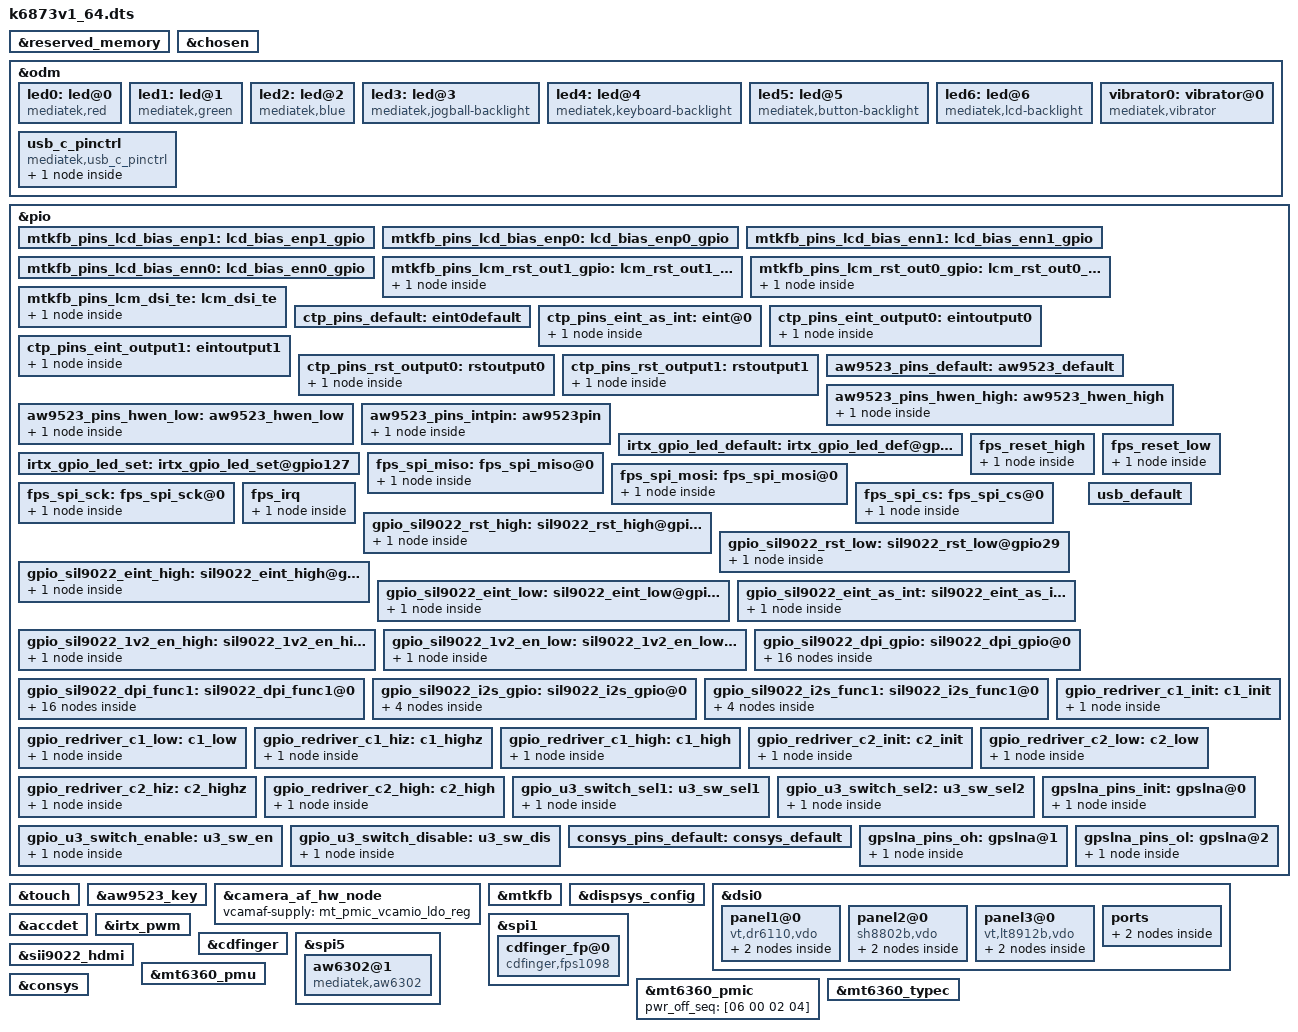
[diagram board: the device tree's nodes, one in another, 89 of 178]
/*
 * Mediatek's mt6873 SoC device tree source
 *
 * Copyright (C) 2016 MediaTek Inc.
 *
 * This program is free software; you can redistribute it and/or modify
 * it under the terms of the GNU General Public License version 2 as
 * published by the Free Software Foundation.
 *
 * This program is distributed in the hope that it will be useful,
 * but WITHOUT ANY WARRANTY; without even the implied warranty of
 * MERCHANTABILITY or FITNESS FOR A PARTICULAR PURPOSE.
 * See http://www.gnu.org/licenses/gpl-2.0.html for more details.
 */
/dts-v1/;
/plugin/;
#include <dt-bindings/interrupt-controller/irq.h>
#include <dt-bindings/interrupt-controller/arm-gic.h>
#include <dt-bindings/pinctrl/mt6873-pinfunc.h>

&reserved_memory {
};

/* chosen */
&chosen {

	atag,videolfb-fb_base_l = <0x7e605000>;
	atag,videolfb-fb_base_h = <0x0>;
	atag,videolfb-islcmfound = <1>;
	atag,videolfb-islcm_inited = <0>;
	atag,videolfb-fps= <6000>;
	atag,videolfb-vramSize= <0x1be0000>;
	atag,videolfb-lcmname=
		"nt35595_fhd_dsi_cmd_truly_nt50358_drv";
};

&odm {
	led0:led@0 {
		compatible = "mediatek,red";
		led_mode = <0>;
		data = <1>;
		pwm_config = <0 0 0 0 0>;
	};
	led1:led@1 {
		compatible = "mediatek,green";
		led_mode = <0>;
		data = <1>;
		pwm_config = <0 0 0 0 0>;
	};
	led2:led@2 {
		compatible = "mediatek,blue";
		led_mode = <0>;
		data = <1>;
		pwm_config = <0 0 0 0 0>;
	};
	led3:led@3 {
		compatible = "mediatek,jogball-backlight";
		led_mode = <0>;
		data = <1>;
		pwm_config = <0 0 0 0 0>;
	};
	led4:led@4 {
		compatible = "mediatek,keyboard-backlight";
		led_mode = <0>;
		data = <1>;
		pwm_config = <0 0 0 0 0>;
	};
	led5:led@5 {
		compatible = "mediatek,button-backlight";
		led_mode = <0>;
		data = <1>;
		pwm_config = <0 0 0 0 0>;
	};
	led6:led@6 {
		compatible = "mediatek,lcd-backlight";
		led_mode = <4>;
		data = <1>;
		pwm_config = <0 1 0 0 0>;
	};
	vibrator0:vibrator@0 {
		compatible = "mediatek,vibrator";
		vib_timer = <25>;
		vib_limit = <9>;
		vib_vol= <9>;
	};
	usb_c_pinctrl:usb_c_pinctrl {
		compatible = "mediatek,usb_c_pinctrl";
	};
};

/* DISPSYS GPIO standardization */

&pio {
	mtkfb_pins_lcd_bias_enp1: lcd_bias_enp1_gpio {
		//pins_cmd_dat {
			//pinmux = <PINMUX_GPIO28__FUNC_GPIO28>;
			//slew-rate = <1>;
			//output-high;
		//};
	};

	mtkfb_pins_lcd_bias_enp0: lcd_bias_enp0_gpio {
		//pins_cmd_dat {
			//pinmux = <PINMUX_GPIO28__FUNC_GPIO28>;
			//slew-rate = <1>;
			//output-low;
		//};
	};

	mtkfb_pins_lcd_bias_enn1: lcd_bias_enn1_gpio {
		//pins_cmd_dat {
			//pinmux = <PINMUX_GPIO29__FUNC_GPIO29>;
			//slew-rate = <1>;
			//output-high;
		//};
	};

	mtkfb_pins_lcd_bias_enn0: lcd_bias_enn0_gpio {
		//pins_cmd_dat {
			//pinmux = <PINMUX_GPIO29__FUNC_GPIO29>;
			//slew-rate = <1>;
			//output-low;
		//};
	};

	mtkfb_pins_lcm_rst_out1_gpio: lcm_rst_out1_gpio {
		pins_cmd_dat {
			pinmux = <PINMUX_GPIO42__FUNC_GPIO42>;
			slew-rate = <1>;
			output-high;
		};
	};

	mtkfb_pins_lcm_rst_out0_gpio: lcm_rst_out0_gpio {
		pins_cmd_dat {
			pinmux = <PINMUX_GPIO42__FUNC_GPIO42>;
			slew-rate = <1>;
			output-low;
		};
	};
	mtkfb_pins_lcm_dsi_te: lcm_dsi_te {
		pins_cmd_dat {
			pinmux = <PINMUX_GPIO41__FUNC_DSI_TE>;
		};
	};
};
/* TOUCH start */
&touch {
	tpd-resolution = <1080 2340>;
	use-tpd-button = <0>;
	tpd-key-num = <3>;
	tpd-key-local= <139 172 158 0>;
	tpd-key-dim-local = <90 883 100 40 230 883 100 40 370 883 100 40 0 0 0 0>;
	tpd-max-touch-num = <5>;
	tpd-filter-enable = <1>;
	tpd-filter-pixel-density = <146>;
	tpd-filter-custom-prameters = <0 0 0 0 0 0 0 0 0 0 0 0>;
	tpd-filter-custom-speed = <0 0 0>;
	pinctrl-names = "default", "state_eint_as_int", "state_eint_output0", "state_eint_output1",
		"state_rst_output0", "state_rst_output1";
	pinctrl-0 = <&ctp_pins_default>;
	pinctrl-1 = <&ctp_pins_eint_as_int>;
	pinctrl-2 = <&ctp_pins_eint_output0>;
	pinctrl-3 = <&ctp_pins_eint_output1>;
	pinctrl-4 = <&ctp_pins_rst_output0>;
	pinctrl-5 = <&ctp_pins_rst_output1>;
	status = "okay";
};

&pio {
	ctp_pins_default: eint0default {
	};
	ctp_pins_eint_as_int: eint@0 {
		pins_cmd_dat {
			pinmux = <PINMUX_GPIO21__FUNC_GPIO21>;
			slew-rate = <0>;
			bias-disable;
		};
	};
	ctp_pins_eint_output0: eintoutput0 {
		pins_cmd_dat {
			pinmux = <PINMUX_GPIO21__FUNC_GPIO21>;
			slew-rate = <1>;
			output-low;
		};
	};
	ctp_pins_eint_output1: eintoutput1 {
		pins_cmd_dat {
			pinmux = <PINMUX_GPIO21__FUNC_GPIO21>;
			slew-rate = <1>;
			output-high;
		};
	};
	ctp_pins_rst_output0: rstoutput0 {
		pins_cmd_dat {
			pinmux = <PINMUX_GPIO20__FUNC_GPIO20>;
			slew-rate = <1>;
			output-low;
		};
	};
	ctp_pins_rst_output1: rstoutput1 {
		pins_cmd_dat {
			pinmux = <PINMUX_GPIO20__FUNC_GPIO20>;
			slew-rate = <1>; 
			output-high;
		}; 
	};
};
/* TOUCH end */
&aw9523_key {
	pinctrl-names = "default","aw9523_shdn_high","aw9523_shdn_low","aw9523_int_pin";
	pinctrl-0 = <&aw9523_pins_default>;
	pinctrl-1 = <&aw9523_pins_hwen_high>;
	pinctrl-2 = <&aw9523_pins_hwen_low>;
	pinctrl-3 = <&aw9523_pins_intpin>;
	status = "okay";
};
&pio {
	aw9523_pins_default: aw9523_default {
	};
	aw9523_pins_hwen_high: aw9523_hwen_high {
	    pins_cmd_dat {
			pinmux = <PINMUX_GPIO5__FUNC_GPIO5>;
			slew-rate = <1>;
			output-high;
		};
	};
	aw9523_pins_hwen_low: aw9523_hwen_low {
	    pins_cmd_dat {
			pinmux = <PINMUX_GPIO5__FUNC_GPIO5>;
			slew-rate = <1>;
			output-low;
		};
	};
    aw9523_pins_intpin: aw9523pin{
        pins_cmd_dat {
            pinmux = <PINMUX_GPIO2__FUNC_GPIO2>;
            slew-rate = <0>;
            bias-pull-up = <00>;
        };
    };
};


&camera_af_hw_node {
	vcamaf-supply = <&mt_pmic_vcamio_ldo_reg>;
	status = "okay";
};

&mtkfb {
	pinctrl-names = "lcd_bias_enp1_gpio", "lcd_bias_enp0_gpio",
		"lcd_bias_enn1_gpio", "lcd_bias_enn0_gpio",
		"lcm_rst_out1_gpio", "lcm_rst_out0_gpio",
		"mode_te_te";
	pinctrl-0 = <&mtkfb_pins_lcd_bias_enp1>;
	pinctrl-1 = <&mtkfb_pins_lcd_bias_enp0>;
	pinctrl-2 = <&mtkfb_pins_lcd_bias_enn1>;
	pinctrl-3 = <&mtkfb_pins_lcd_bias_enn0>;
	pinctrl-4 = <&mtkfb_pins_lcm_rst_out1_gpio>;
	pinctrl-5 = <&mtkfb_pins_lcm_rst_out0_gpio>;
	pinctrl-6 = <&mtkfb_pins_lcm_dsi_te>;
	status = "okay";
};

&dispsys_config {
	pinctrl-names =
		"lcm_rst_out1_gpio", "lcm_rst_out0_gpio",
		"mode_te_te";
	pinctrl-0 = <&mtkfb_pins_lcm_rst_out1_gpio>;
	pinctrl-1 = <&mtkfb_pins_lcm_rst_out0_gpio>;
	pinctrl-2 = <&mtkfb_pins_lcm_dsi_te>;
	status = "okay";
};

&dsi0 {
	status = "okay";
	#address-cells = <1>;
	#size-cells = <0>;
	panel1@0 {
		compatible = "vt,dr6110,vdo";
		reg = <0>;
		pm-enable-gpios = <&pio 41 0>;
		reset-gpios = <&pio 42 0>;
		bias-gpios = <&pio 87 0>,
			<&pio 88 0>;
		pinctrl-names = "default";
		port {
			panel_in1: endpoint {
				remote-endpoint = <&dsi_out>;
			};
		};
	};
	panel2@0 {
		compatible = "sh8802b,vdo";
		reg = <1>;
		pm-enable-gpios = <&pio 41 0>;
		reset-gpios = <&pio 42 0>;
		bias-gpios = <&pio 87 0>,
			<&pio 88 0>;
		pinctrl-names = "default";
		port {
			panel_in2: endpoint {
				remote-endpoint = <&dsi_out>;
			};
		};
	};
	panel3@0 {
		compatible = "vt,lt8912b,vdo";
		reg = <2>;
		pm-enable-gpios = <&pio 41 0>;
		reset-gpios = <&pio 42 0>;
		bias-gpios = <&pio 87 0>,
			<&pio 88 0>;
		pinctrl-names = "default";
		port {
			panel_in3: endpoint {
				remote-endpoint = <&dsi_out>;
			};
		};
	};
	ports {
		port {
			dsi_out: endpoint {
				remote-endpoint = <&panel_in1>;
			};
		};
	};
};

/* accdet start */
&accdet {
	/* accdet micbias voltage: 0x09:2.85v 0x08:2.8v 0x07,
	 * 2.7v;0x05,2.5v;0x02,1.9v
	 */
	accdet-mic-vol = <8>;
	/* accdet pwm_width, pwm_thresh, fall_delay, rise_delay
	 * debounce0, debounce1, debounce3, debounce4
	 * eint pwm_width, eint pwm_thresh
	 * eint deb(debounce0, debounce1, debounce2, debounce3), inv_debounce
	 */
	headset-mode-setting = <0x500 0x500 1 0x1f0
				0x800 0x800 0x20 0x44
				0x4 0x1
				0x5 0x3 0x3 0x5 0xe>;
	accdet-plugout-debounce = <1>;
	/*1:ACC mode, 2:low cost without in bias, 6:low cost with in bias*/
	accdet-mic-mode = <2>;
	/*0--MD_MAX--UP_MAX--DW_MAX*/
	headset-three-key-threshold = <0 80 220 400>;
	headset-three-key-threshold-CDD = <0 121 192 600>;
	/*0--MD_MAX--VOICE_MAX--UP_MAX--DW_MAX*/
	headset-four-key-threshold = <0 58 121 192 400>;

	/* select VTH to 2v and 500k, use internal resitance */
	eint_use_ext_res = <0>;
	status = "okay";
};
/* accdet end */

/* IRTX GPIO Start */
&irtx_pwm {
	pinctrl-names = "irtx_gpio_led_default", "irtx_gpio_led_set";
	pinctrl-0 = <&irtx_gpio_led_default>;
	pinctrl-1 = <&irtx_gpio_led_set>;
	status = "okay";
};
&pio {
	/* IRTX GPIO Settings -Start */
	/* default: GPIO0, output, high */
	irtx_gpio_led_default:irtx_gpio_led_def@gpio127 {
		//pins_cmd_dat {
			//pinmux = <PINMUX_GPIO127__FUNC_GPIO127>;
			//slew-rate = <1>;
			//bias-disable;
			//output-low;
			//input-schmitt-enable = <0>;
		//};
	};

	irtx_gpio_led_set:irtx_gpio_led_set@gpio127 {
		//pins_cmd_dat {
			//pinmux = <PINMUX_GPIO127__FUNC_PWM_3>;
			//slew-rate = <1>;
			//output-high;
		//};
	};
}; /* IRTX GPIO Settings -End */

/************Cdfinger FINGERPRINT bengin *********/
&pio {
	fps_reset_high: fps_reset_high {
		pins_cmd_dat {
			pinmux = <PINMUX_GPIO14__FUNC_GPIO14>;
			slew-rate = <1>;
			bias-disable;
			output-high;
		};
	};
	fps_reset_low: fps_reset_low {
		pins_cmd_dat {
			pinmux = <PINMUX_GPIO14__FUNC_GPIO14>;
			slew-rate = <1>;
			bias-disable;
			output-low;
		};
	};
	fps_spi_miso:fps_spi_miso@0{
		pins_cmd_dat {
			pinmux = <PINMUX_GPIO158__FUNC_SPI1_A_MI>;
			slew-rate = <0>;
			bias-disable;
			output-low;
		};
	};
	fps_spi_mosi:fps_spi_mosi@0{
		pins_cmd_dat {
			pinmux = <PINMUX_GPIO159__FUNC_SPI1_A_MO>;
			slew-rate = <1>;
			bias-disable;
			output-low;
		};
	};
	fps_spi_sck:fps_spi_sck@0{
		pins_cmd_dat {
			pinmux = <PINMUX_GPIO156__FUNC_SPI1_A_CLK>;
			slew-rate = <1>;
			bias-disable;
			output-low;
		};
	};
	fps_spi_cs:fps_spi_cs@0{
		pins_cmd_dat {
			pinmux = <PINMUX_GPIO157__FUNC_SPI1_A_CSB>;
			slew-rate = <1>;
			bias-pull-up = <11>;
			bias-disable;
			output-low;
		};
	};
	fps_irq: fps_irq {
		pins_cmd_dat {
			pinmux = <PINMUX_GPIO15__FUNC_GPIO15>;
			slew-rate = <0>;
			bias-pull-down = <00>;
			bias-disable;
			output-low;
		};
	};
};

&spi1 {
	#address-cells = <1>;
	#size-cells = <0>;
  
	 cdfinger_fp@0{                               
		compatible = "cdfinger,fps1098";		
		reg = <0x0>;                                
		spi-max-frequency = <0x10000000>;	          
		status = "okay";                            
	 };                                       
	                                       
};

&cdfinger {
	interrupt-parent = <&pio>;
	interrupts = <15 1 1 0>;
	/*interrupts = <15 IRQ_TYPE_EDGE_RISING 1 0>;*/
	vfp-supply = <&mt_pmic_vfp_ldo_reg>;
	vdd_ldo_enable = <0>;
	vio_ldo_enable = <0>;
	config_spi_pin = <1>;
	
	
	pinctrl-names = "fingerprint_reset_high",
		"fingerprint_reset_low",
		"fingerprint_spi_miso",
		"fingerprint_spi_mosi",
		"fingerprint_spi_sck",
		"fingerprint_spi_cs",
		"fingerprint_irq";
	pinctrl-0 = <&fps_reset_high>;
	pinctrl-1 = <&fps_reset_low>;
	pinctrl-2 = <&fps_spi_miso>;
	pinctrl-3 = <&fps_spi_mosi>;
	pinctrl-4 = <&fps_spi_sck>;
	pinctrl-5 = <&fps_spi_cs>;
	pinctrl-6 = <&fps_irq>;
	status = "okay";

};
/************Cdfinger FINGERPRINT end *********/

&spi5 {
    #address-cells = <1>;
    #size-cells = <0>;
    aw6302@1 {
        compatible = "mediatek,aw6302";
        reg = <0>;
        spi-max-frequency = <1500000>;
        status = "okay";
    };
};

/*sil9022 hdmi start*/
&sii9022_hdmi {
	pinctrl-names = "sil9022_rst_high","sil9022_rst_low","sil9022_eint_high","sil9022_eint_low","sil9022_eint_as_int",
			"sil9022_1v2_en_high","sil9022_1v2_en_low","sil9022_dpi_gpio","sil9022_dpi_func1","sil9022_i2s_gpio","sil9022_i2s_func1";		
	pinctrl-0 = <&gpio_sil9022_rst_high>;
	pinctrl-1 = <&gpio_sil9022_rst_low>;
	pinctrl-2 = <&gpio_sil9022_eint_high>;
	pinctrl-3 = <&gpio_sil9022_eint_low>;
	pinctrl-4 = <&gpio_sil9022_eint_as_int>;
	pinctrl-5 = <&gpio_sil9022_1v2_en_high>;
	pinctrl-6 = <&gpio_sil9022_1v2_en_low>;
	pinctrl-7 = <&gpio_sil9022_dpi_gpio>;
	pinctrl-8 = <&gpio_sil9022_dpi_func1>;
	pinctrl-9 = <&gpio_sil9022_i2s_gpio>;
	pinctrl-10 = <&gpio_sil9022_i2s_func1>;	
	status = "okay";
};

&pio {

	gpio_sil9022_rst_high:sil9022_rst_high@gpio29 {
		pins_cmd_dat {
			pinmux = <PINMUX_GPIO29__FUNC_GPIO29>;
			slew-rate = <1>;
			output-high;
		};
	};

	gpio_sil9022_rst_low:sil9022_rst_low@gpio29 {
		pins_cmd_dat {
			pinmux = <PINMUX_GPIO29__FUNC_GPIO29>;
			slew-rate = <1>;
			output-low;
		};
	};
	
	gpio_sil9022_eint_high:sil9022_eint_high@gpio7 {
		pins_cmd_dat {
			pinmux = <PINMUX_GPIO7__FUNC_GPIO7>;
			slew-rate = <1>;
			output-high;
		};
	};

	gpio_sil9022_eint_low:sil9022_eint_low@gpio7 {
		pins_cmd_dat {
			pinmux = <PINMUX_GPIO7__FUNC_GPIO7>;
			slew-rate = <1>;
			output-low;
		};
	};
	
	gpio_sil9022_eint_as_int:sil9022_eint_as_int@7 {
		pins_cmd_dat {
			pinmux = <PINMUX_GPIO7__FUNC_GPIO7>;
			slew-rate = <0>;
			bias-disable;
		};
	};	

	gpio_sil9022_1v2_en_high:sil9022_1v2_en_high@gpio18 {
		pins_cmd_dat {
			pinmux = <PINMUX_GPIO18__FUNC_GPIO18>;
			slew-rate = <1>;
			output-high;
		};
	};
	
	gpio_sil9022_1v2_en_low:sil9022_1v2_en_low@gpio18 {
		pins_cmd_dat {
			pinmux = <PINMUX_GPIO18__FUNC_GPIO18>;
			slew-rate = <1>;
			output-low;
		};
	};	

	gpio_sil9022_dpi_gpio: sil9022_dpi_gpio@0 {
		pins_cmd0_dat {
			pinmux = <PINMUX_GPIO96__FUNC_GPIO96>;
			slew-rate = <1>;
			output-low;
			bias-disable;
			drive-strength= <7>;
		};
		pins_cmd1_dat {
			pinmux = <PINMUX_GPIO97__FUNC_GPIO97>;
			slew-rate = <1>;
			output-low;
			bias-disable;
			drive-strength= <7>;
		};
		pins_cmd2_dat {
			pinmux = <PINMUX_GPIO98__FUNC_GPIO98>;
			slew-rate = <1>;
			output-low;
			bias-disable;
			drive-strength= <7>;
		};
		pins_cmd3_dat {
			pinmux = <PINMUX_GPIO99__FUNC_GPIO99>;
			slew-rate = <1>;
			output-low;
			bias-disable;
			drive-strength= <7>;
		};
		pins_cmd4_dat {
			pinmux = <PINMUX_GPIO100__FUNC_GPIO100>;
			slew-rate = <1>;
			output-low;
			bias-disable;
			drive-strength= <7>;
		};
		pins_cmd5_dat {
			pinmux = <PINMUX_GPIO101__FUNC_GPIO101>;
			slew-rate = <1>;
			output-low;
			bias-disable;
			drive-strength= <7>;
		};
		pins_cmd6_dat {
			pinmux = <PINMUX_GPIO102__FUNC_GPIO102>;
			slew-rate = <1>;
			output-low;
			bias-disable;
			drive-strength= <7>;
		};
		pins_cmd7_dat {
			pinmux = <PINMUX_GPIO103__FUNC_GPIO103>;
			slew-rate = <1>;
			output-low;
			bias-disable;
			drive-strength= <7>;
		};
		pins_cmd8_dat {
			pinmux = <PINMUX_GPIO104__FUNC_GPIO104>;
			slew-rate = <1>;
			output-low;
			bias-disable;
			drive-strength= <7>;
		};
		pins_cmd9_dat {
			pinmux = <PINMUX_GPIO105__FUNC_GPIO105>;
			slew-rate = <1>;
			output-low;
			bias-disable;
			drive-strength= <7>;
		};
		pins_cmd10_dat {
			pinmux = <PINMUX_GPIO106__FUNC_GPIO106>;
			slew-rate = <1>;
			output-low;
			bias-disable;
			drive-strength= <7>;
		};
		pins_cmd11_dat {
			pinmux = <PINMUX_GPIO110__FUNC_GPIO110>;
			slew-rate = <1>;
			output-low;
			bias-disable;
			drive-strength= <7>;
		};
		pins_cmd12_dat {
			pinmux = <PINMUX_GPIO109__FUNC_GPIO109>;
			slew-rate = <1>;
			output-low;
			bias-disable;
			drive-strength= <7>;
		};
		pins_cmd13_dat {
			pinmux = <PINMUX_GPIO112__FUNC_GPIO112>;
			slew-rate = <1>;
			output-low;
			bias-disable;
			drive-strength= <7>;
		};
		pins_cmd14_dat {
			pinmux = <PINMUX_GPIO113__FUNC_GPIO113>;
			slew-rate = <1>;
			output-low;
			bias-disable;
			drive-strength= <7>;
		};
		pins_cmd15_dat {
			pinmux = <PINMUX_GPIO111__FUNC_GPIO111>;
			slew-rate = <1>;
			output-low;
			bias-disable;
			drive-strength= <7>;
		};
	};
	
	gpio_sil9022_dpi_func1: sil9022_dpi_func1@0 {
		pins_cmd0_dat {
			pinmux = <PINMUX_GPIO96__FUNC_DPI_D0>;
			bias-disable;
			drive-strength= <7>;
		};
		pins_cmd1_dat {
			pinmux = <PINMUX_GPIO97__FUNC_DPI_D1>;
			bias-disable;
			drive-strength= <7>;
		};
		pins_cmd2_dat {
			pinmux = <PINMUX_GPIO98__FUNC_DPI_D2>;
			bias-disable;
			drive-strength= <7>;
		};
		pins_cmd3_dat {
			pinmux = <PINMUX_GPIO99__FUNC_DPI_D3>;
			bias-disable;
			drive-strength= <7>;
		};
		pins_cmd4_dat {
			pinmux = <PINMUX_GPIO100__FUNC_DPI_D4>;
			bias-disable;
			drive-strength= <7>;
		};
		pins_cmd5_dat {
			pinmux = <PINMUX_GPIO101__FUNC_DPI_D5>;
			bias-disable;
			drive-strength= <7>;
		};
		pins_cmd6_dat {
			pinmux = <PINMUX_GPIO102__FUNC_DPI_D6>;
			bias-disable;
			drive-strength= <7>;
		};
		pins_cmd7_dat {
			pinmux = <PINMUX_GPIO103__FUNC_DPI_D7>;
			bias-disable;
			drive-strength= <7>;
		};
		pins_cmd8_dat {
			pinmux = <PINMUX_GPIO104__FUNC_DPI_D8>;
			bias-disable;
			drive-strength= <7>;
		};
		pins_cmd9_dat {
			pinmux = <PINMUX_GPIO105__FUNC_DPI_D9>;
			bias-disable;
			drive-strength= <7>;
		};
		pins_cmd10_dat {
			pinmux = <PINMUX_GPIO106__FUNC_DPI_D10>;
			bias-disable;
			drive-strength= <7>;
		};
		pins_cmd11_dat {
			pinmux = <PINMUX_GPIO110__FUNC_DPI_D11>;
			bias-disable;
			drive-strength= <7>;
		};
		pins_cmd12_dat {
			pinmux = <PINMUX_GPIO109__FUNC_DPI_DE>;
			bias-disable;
			drive-strength= <7>;
		};
		pins_cmd13_dat {
			pinmux = <PINMUX_GPIO112__FUNC_DPI_CK>;
			bias-disable;
			drive-strength= <7>;
		};
		pins_cmd14_dat {
			pinmux = <PINMUX_GPIO113__FUNC_DPI_HSYNC>;
			bias-disable;
			drive-strength= <7>;
		};
		pins_cmd15_dat {
			pinmux = <PINMUX_GPIO111__FUNC_DPI_VSYNC>;
			bias-disable;
			drive-strength= <7>;
		};
	};

	gpio_sil9022_i2s_gpio: sil9022_i2s_gpio@0 {
		pins_cmd0_dat {
			pinmux = <PINMUX_GPIO32__FUNC_GPIO32>;
			slew-rate = <1>;
			output-low;
		};
		pins_cmd1_dat {
			pinmux = <PINMUX_GPIO33__FUNC_GPIO33>;
			slew-rate = <1>;
			output-low;
		};
		pins_cmd2_dat {
			pinmux = <PINMUX_GPIO35__FUNC_GPIO35>;
			slew-rate = <1>;
			output-low;
		};
		pins_cmd3_dat {
			pinmux = <PINMUX_GPIO31__FUNC_GPIO31>;
			slew-rate = <1>;
			output-low;
		};
	};
	
	gpio_sil9022_i2s_func1: sil9022_i2s_func1@0 {
		pins_cmd0_dat {
			pinmux = <PINMUX_GPIO32__FUNC_I2S3_BCK>;
		};
		pins_cmd1_dat {
			pinmux = <PINMUX_GPIO33__FUNC_I2S3_LRCK>;
		};
		pins_cmd2_dat {
			pinmux = <PINMUX_GPIO35__FUNC_I2S3_DO>;
		};
		pins_cmd3_dat {
			pinmux = <PINMUX_GPIO31__FUNC_I2S3_MCK>;
		};
	};
	
};
/*sil9022 hdmi end*/

&mt6360_pmu {
	mt6360,intr_gpio_num = <24>; /* direct defined GPIO num */
	mt6360,intr_gpio = <&pio 24 0x0>;
};

&mt6360_pmic {
	pwr_off_seq = [06 00 02 04];
};

&mt6360_typec {
	mt6360pd,intr_gpio_num = <25>; /* direct defined GPIO num */
	mt6360pd,intr_gpio = <&pio 25 0x0>;
	mt6360pd,pcb_gpio = <&pio 19 0x0>;
	mt6360pd,pcb_gpio_num = <19>;
};

/* USB SWITCH GPIO start */
&pio {
	usb_default: usb_default {
	};

	gpio_redriver_c1_init: c1_init {
		pins_cmd_dat {
			pinmux = <PINMUX_GPIO107__FUNC_GPIO107>;
			slew-rate = <1>;
			output-low;
		};
	};

	gpio_redriver_c1_low: c1_low {
		pins_cmd_dat {
			pinmux = <PINMUX_GPIO107__FUNC_GPIO107>;
			slew-rate = <1>;
			output-low;
		};
	};

	gpio_redriver_c1_hiz: c1_highz {
		pins_cmd_dat {
			pinmux = <PINMUX_GPIO107__FUNC_GPIO107>;
			slew-rate= <0>;
			bias-disable;
		};
	};

	gpio_redriver_c1_high: c1_high {
		pins_cmd_dat {
			pinmux = <PINMUX_GPIO107__FUNC_GPIO107>;
			slew-rate = <1>;
			output-high;
		};
	};

	gpio_redriver_c2_init: c2_init {
		pins_cmd_dat {
			pinmux = <PINMUX_GPIO108__FUNC_GPIO108>;
			slew-rate = <1>;
			output-low;
		};
	};

	gpio_redriver_c2_low: c2_low {
		pins_cmd_dat {
			pinmux = <PINMUX_GPIO108__FUNC_GPIO108>;
			slew-rate = <1>;
			output-low;
		};
	};

	gpio_redriver_c2_hiz: c2_highz {
		pins_cmd_dat {
			pinmux = <PINMUX_GPIO108__FUNC_GPIO108>;
			slew-rate= <0>;
			bias-disable;
		};
	};

	gpio_redriver_c2_high: c2_high {
		pins_cmd_dat {
			pinmux = <PINMUX_GPIO108__FUNC_GPIO108>;
			slew-rate = <1>;
			output-high;
		};
	};

	gpio_u3_switch_sel1: u3_sw_sel1 {
		pins_cmd_dat {
			pinmux = <PINMUX_GPIO131__FUNC_GPIO131>;
			slew-rate = <1>;
			output-low;
		};
	};

	gpio_u3_switch_sel2: u3_sw_sel2 {
		pins_cmd_dat {
			pinmux = <PINMUX_GPIO131__FUNC_GPIO131>;
			slew-rate = <1>;
			output-high;
		};
	};

	gpio_u3_switch_enable: u3_sw_en {
		pins_cmd_dat {
			pinmux = <PINMUX_GPIO132__FUNC_GPIO132>;
			slew-rate = <1>;
			output-low;
		};
	};

	gpio_u3_switch_disable: u3_sw_dis {
		pins_cmd_dat {
			pinmux = <PINMUX_GPIO132__FUNC_GPIO132>;
			slew-rate = <1>;
			output-high;
		};
	};
};

&usb_c_pinctrl {
	pinctrl-names = "usb_default",
		"redrv_c1_init",
		"redrv_c1_low",
		"redrv_c1_hiz",
		"redrv_c1_high",
		"redrv_c2_init",
		"redrv_c2_low",
		"redrv_c2_hiz",
		"redrv_c2_high",
		"switch_sel1",
		"switch_sel2",
		"switch_enable",
		"switch_disable";

	pinctrl-0 = <&usb_default>;
	pinctrl-1 = <&gpio_redriver_c1_init>;
	pinctrl-2 = <&gpio_redriver_c1_low>;
	pinctrl-3 = <&gpio_redriver_c1_hiz>;
	pinctrl-4 = <&gpio_redriver_c1_high>;
	pinctrl-5 = <&gpio_redriver_c2_init>;
	pinctrl-6 = <&gpio_redriver_c2_low>;
	pinctrl-7 = <&gpio_redriver_c2_hiz>;
	pinctrl-8 = <&gpio_redriver_c2_high>;
	pinctrl-9 = <&gpio_u3_switch_sel1>;
	pinctrl-10 = <&gpio_u3_switch_sel2>;
	pinctrl-11 = <&gpio_u3_switch_enable>;
	pinctrl-12 = <&gpio_u3_switch_disable>;
	status = "okay";

	usb_switch-data {
		en_pin_num = <132>;
		en_pin_val = <0>;
		sel_pin_num = <131>;
		sel_pin_val = <1>;
		c1_pin_num = <107>;
		c1_pin_val = <2>;
		c2_pin_num = <108>;
		c2_pin_val = <2>;
	};
};
/* USB SWITCH GPIO end */

/* CONSYS GPIO standardization */
&pio {
	consys_pins_default: consys_default {
	};
	gpslna_pins_init: gpslna@0 {
		pins_cmd_dat {
			pinmux = <PINMUX_GPIO162__FUNC_GPIO162>;
			output-low;
		};
	};
	gpslna_pins_oh: gpslna@1 {
		pins_cmd_dat {
			pinmux = <PINMUX_GPIO162__FUNC_GPS_L1_ELNA_EN>;
		};
	};
	gpslna_pins_ol: gpslna@2 {
		pins_cmd_dat {
			pinmux = <PINMUX_GPIO162__FUNC_GPIO162>;
			output-low;
		};
	};
};
&consys {
	pinctrl-names = "default", "gps_lna_state_init",
		"gps_lna_state_oh", "gps_lna_state_ol";
	pinctrl-0 = <&consys_pins_default>;
	pinctrl-1 = <&gpslna_pins_init>;
	pinctrl-2 = <&gpslna_pins_oh>;
	pinctrl-3 = <&gpslna_pins_ol>;
	status = "okay";
};
/* CONSYS end */

#include "mediatek/cust_mt6873_camera.dtsi"
//#include "mediatek/cust_mt6873_touch_1080x2280.dtsi"
#include "mediatek/cust_mt6873_touch_1080x2340.dtsi"
#include <k6873v1_64/cust.dtsi>
/*End of this file, DO NOT ADD ANYTHING HERE*/
